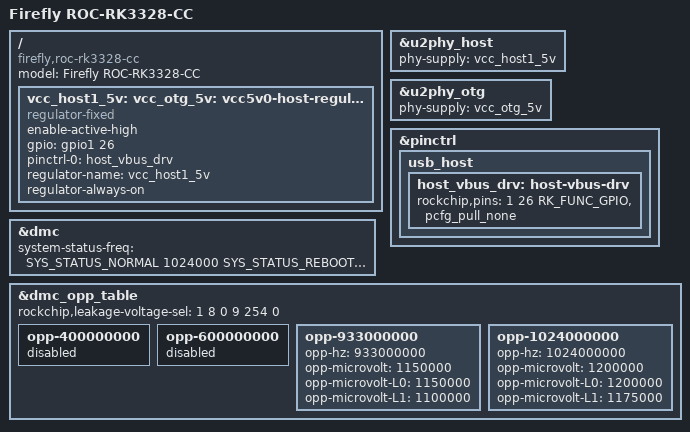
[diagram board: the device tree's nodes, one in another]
/dts-v1/;
#include "rk3328-firefly-port.dtsi"

/ {
	model = "Firefly ROC-RK3328-CC";
	compatible = "firefly,roc-rk3328-cc", "rockchip,rk3328";
	
	vcc_host1_5v: vcc_otg_5v: vcc5v0-host-regulator {
		compatible = "regulator-fixed";
		enable-active-high;
		gpio = <&gpio1 26 GPIO_ACTIVE_HIGH>;
		pinctrl-names = "default";
		pinctrl-0 = <&host_vbus_drv>;
		regulator-name = "vcc_host1_5v";
		regulator-always-on;
	};

};

&u2phy_host {
	phy-supply = <&vcc_host1_5v>;
	status = "okay";
};

&u2phy_otg {
	phy-supply = <&vcc_otg_5v>;
	status = "okay";
};

&pinctrl {
	usb_host {
		host_vbus_drv: host-vbus-drv {
			rockchip,pins =
				<1 26 RK_FUNC_GPIO &pcfg_pull_none>;
		};
	};
};

&dmc {
	system-status-freq = <
		/*system status         freq(KHz)*/
		SYS_STATUS_NORMAL       1024000
		SYS_STATUS_REBOOT       1024000
		SYS_STATUS_SUSPEND      1024000
		SYS_STATUS_VIDEO_1080P  1024000
		SYS_STATUS_VIDEO_4K     1024000
		SYS_STATUS_VIDEO_4K_10B 1024000
		SYS_STATUS_PERFORMANCE  1024000
		SYS_STATUS_BOOST        1024000
	>;
};

&dmc_opp_table {
	rockchip,leakage-voltage-sel = <
		1   8     0
		9   254   0
	>;
	
	opp-400000000 {
		status = "disabled";
	};

	opp-600000000 {
		status = "disabled";
	};

	opp-933000000 {
		opp-hz = /bits/ 64 <933000000>;
		opp-microvolt = <1150000>;
		opp-microvolt-L0 = <1150000>;
		opp-microvolt-L1 = <1100000>;
	};
	opp-1024000000 {
		opp-hz = /bits/ 64 <1024000000>;
		opp-microvolt = <1200000>;
		opp-microvolt-L0 = <1200000>;
		opp-microvolt-L1 = <1175000>;
	};
};
